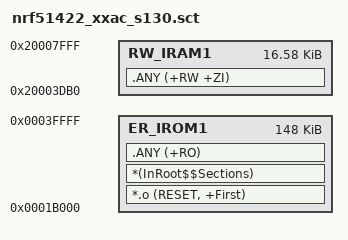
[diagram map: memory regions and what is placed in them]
; *************************************************************
; *** Scatter-Loading Description File generated by uVision ***
; *************************************************************

LR_IROM1 0x0001B000 0x00025000  {    ; load region size_region
  ER_IROM1 0x0001B000 0x00025000  {  ; load address = execution address
   *.o (RESET, +First)
   *(InRoot$$Sections)
   .ANY (+RO)
  }
  RW_IRAM1 0x20003DB0 0x00004250  {  ; RW data
   .ANY (+RW +ZI)
  }
}

